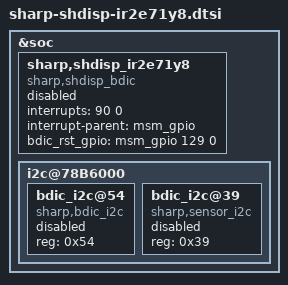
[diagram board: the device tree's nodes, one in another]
/* Copyright (c) 2014, The Linux Foundation. All rights reserved.
 *
 * This program is free software; you can redistribute it and/or modify
 * it under the terms of the GNU General Public License version 2 and
 * only version 2 as published by the Free Software Foundation.
 *
 * This program is distributed in the hope that it will be useful,
 * but WITHOUT ANY WARRANTY; without even the implied warranty of
 * MERCHANTABILITY or FITNESS FOR A PARTICULAR PURPOSE.  See the
 * GNU General Public License for more details.
 */

&soc {
	/*---------------------*/
	/* backlight IC        */
	/*---------------------*/
	sharp,shdisp_ir2e71y8 {
		compatible = "sharp,shdisp_bdic";
		status = "disable";
		interrupts = <90 0>;
		interrupt-parent = <&msm_gpio>;
		bdic_rst_gpio = <&msm_gpio 129 0>;
	};

	i2c@78B6000 {
		bdic_i2c@54 {
			compatible = "sharp,bdic_i2c";
			status = "disable";
			reg = <0x54>;
		};

		bdic_i2c@39 {
			compatible = "sharp,sensor_i2c";
			status = "disable";
			reg = <0x39>;
		};
	};
};
